# MCXN947_cm33_core0 register map
Vendor: nxp.com; File version: 1.0
CPU: CM33 r2p0, little endian, MPU, FPU, VTOR, 3 interrupt priority bits
Registers are 32-bit, read-write, reset 0x0 unless marked. A register's access mark holds for its fields unless they carry their own. Offsets are from the block's base; [hi:lo] are bit positions; {n}, {i} and the like mark numbered series.

## CTIMER0 — CTIMER
Base 0x4000C000
Same registers: CTIMER1 0x4000D000, CTIMER2 0x4000E000, CTIMER3 0x4000F000, CTIMER4 0x40010000
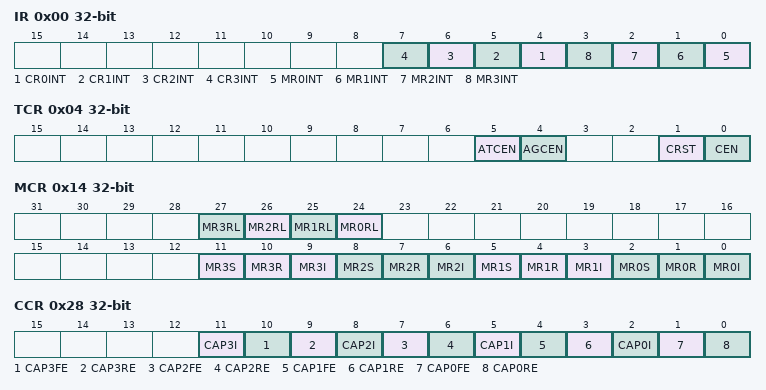
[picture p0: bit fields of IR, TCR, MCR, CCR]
0x00 IR — Interrupt
  [n+4] CR{n}INT (n=0..3) — Interrupt Flag for Capture Channel {n} Event
  [n] MR{n}INT (n=0..3) — Interrupt Flag for Match Channel {n} Event
0x04 TCR — Timer Control
  [5] ATCEN — Allow Trigger Count Enable
    0=DISABLE; 1=ENABLE
  [4] AGCEN — Allow Global Count Enable
    0=DISABLE; 1=ENABLE
  [1] CRST — Counter Reset Enable
    0=DISABLED; 1=ENABLED
  [0] CEN — Counter Enable
    0=DISABLED; 1=ENABLED
0x08 TC — Timer Counter
  [31:0] TCVAL — Timer Counter Value
0x0C PR — Prescale
  [31:0] PRVAL — Prescale Reload Value
0x10 PC — Prescale Counter
  [31:0] PCVAL — Prescale Counter Value
0x14 MCR — Match Control
  [n+24] MR{n}RL (n=0..3) — Reload MR
    0=Does not reload; 1=Reloads
  [11] MR3S — Stop on MR3
    0=Does not stop; 1=Stops
  [3n+1] MR{n}R (n=0..3) — Reset on MR{n}
    0=Does not reset; 1=Resets
  [3n] MR{n}I (n=0..3) — Interrupt on MR{n}
    0=Does not generate; 1=Generates
  [8] MR2S — Stop on MR2
    0=Does not stop; 1=Stops
  [5] MR1S — Stop on MR1
    0=MRIS_0 (Does not stop); 1=MRIS_1 (Stops)
  [2] MR0S — Stop on MR0
    0=Does not stop; 1=Stops
{0x18+4i} MR[{i}] (i=0..3) — Match
  [31:0] MATCH — Timer Counter Match Value
0x28 CCR — Capture Control
  [11] CAP3I — Generate Interrupt on Channel 3 Capture Event
    0=Does not generate; 1=Generates
  [10] CAP3FE — Falling Edge of Capture Channel 3
    0=Does not load; 1=Loads
  [9] CAP3RE — Rising Edge of Capture Channel 3
    0=Does not load; 1=Loads
  [8] CAP2I — Generate Interrupt on Channel 2 Capture Event
    0=Does not generate; 1=Generates
  [7] CAP2FE — Falling Edge of Capture Channel 2
    0=Does not load; 1=Loads
  [6] CAP2RE — Rising Edge of Capture Channel 2
    0=Does not load; 1=Loads
  [5] CAP1I — Generate Interrupt on Channel 1 Capture Event
    0=Does not generates; 1=Generates
  [4] CAP1FE — Falling Edge of Capture Channel 1
    0=Does not load; 1=Loads
  [3] CAP1RE — Rising Edge of Capture Channel 1
    0=Does not load; 1=Loads
  [2] CAP0I — Generate Interrupt on Channel 0 Capture Event
    0=Does not generate; 1=CAPOI_1 (Generates)
  [1] CAP0FE — Falling Edge of Capture Channel 0
    0=Does not load; 1=CAPOFE_1 (Loads)
  [0] CAP0RE — Rising Edge of Capture Channel 0
    0=Does not load; 1=CAPORE_1 (Loads)
{0x2C+4i} CR[{i}] (i=0..3) ro — Capture
  [31:0] CAP — Timer Counter Capture Value
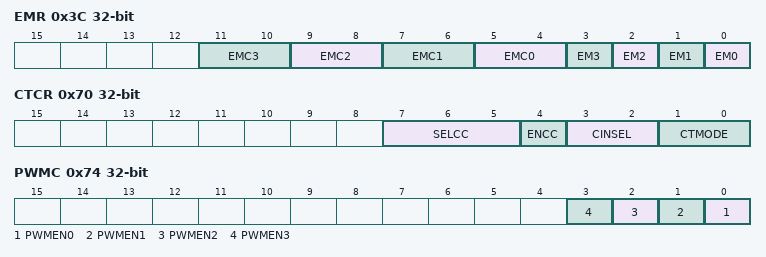
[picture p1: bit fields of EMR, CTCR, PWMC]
0x3C EMR — External Match
  [2n+5:2n+4] EMC{n} (n=0..3) — External Match Control {n}
    0=DO_NOTHING (Does nothing); 1=CLEAR (Goes low); 2=SET (Goes high); 3=TOGGLE (Toggles)
  [n] EM{n} (n=0..3) — External Match {n}
    0=CLEAR (Low); 1=SET (High)
0x70 CTCR — Count Control
  [7:5] SELCC — Edge Select
    0=CHANNEL_0_RISING (Capture channel 0 rising edge); 1=CHANNEL_0_FALLING (Capture channel 0 falling edge); 2=CHANNEL_1_RISING (Capture channel 1 rising edge); 3=CHANNEL_1_FALLING (Capture channel 1 falling edge); 4=CHANNEL_2_RISING (Capture channel 2 rising edge); 5=CHANNEL_2_FALLING (Capture channel 2 falling edge)
  [4] ENCC — Capture Channel Enable
  [3:2] CINSEL — Count Input Select
    {v}=CHANNEL_{v} (Channel {v}, CAPn[{v}] for CTIMERn) (v=0..3)
  [1:0] CTMODE — Counter Timer Mode
    0=TIMER (Timer mode); 1=COUNTER_RISING_EDGE (Counter mode rising edge); 2=COUNTER_FALLING_EDGE (Counter mode falling edge); 3=COUNTER_DUAL_EDGE (Counter mode dual edge)
0x74 PWMC — PWM Control
  [all] fields
    0=MATCH (Disable); 1=PWM (Enable)
  [n] PWMEN{n} (n=0..3) — PWM Mode Enable for Channel {n}
{0x78+4i} MSR[{i}] (i=0..3) — Match Shadow
  [31:0] MATCH_SHADOW — Timer Counter Match Shadow Value
